# apollo3p register map
Vendor: Ambiq Micro; Series: Apollo; File version: 1.0
CPU: CM4 r1p0, little endian, MPU, FPU, I-cache, D-cache, VTOR, ITCM, DTCM, 3 interrupt priority bits, 0 interrupts
Registers are 32-bit, read-write, reset 0x0 unless marked. A register's access mark holds for its fields unless they carry their own. Offsets are from the block's base; [hi:lo] are bit positions; {n}, {i} and the like mark numbered series; 'fields as' and 'values as' point back to an identical list.

## MCUCTRL — MCU Miscellaneous Control Logic
Base 0x40020000
0x00 CHIPPN reset 0x6000000 — Chip Information Register
  [31:0] PARTNUM — BCD part number.
    0x7000000=APOLLO3P (Apollo3 Blue Plus part number is 0x07xxxxxx.); 0x6000000=APOLLO3 (Apollo3 Blue part number is 0x06xxxxxx.); 0x3000000=APOLLO2 (Apollo2 part number is 0x03xxxxxx.); 0x1000000=APOLLO (Apollo part number is 0x01xxxxxx.); 0xFF000000=PN_M (Mask for the part number field.); 24=PN_S (Bit position for the part number field.); 0xF00000=FLASHSIZE_M (Mask for the FLASH_SIZE field. Values: 0: 16KB 1: 32KB 2: 64KB 3: 128KB 4: 256KB 5: 512KB 6: 1MB 7: 2MB 8: 1.5MB); 20=FLASHSIZE_S (Bit position for the FLASH_SIZE field.); 0xF0000=SRAMSIZE_M (Mask for the SRAM_SIZE field. Values: 0: 16KB 1: 32KB 2: 64KB 3: 128KB 4: 256KB 5: 512KB 6: 1MB 7: 384KB 8: 768KB); 16=SRAMSIZE_S (Bit position for the SRAM_SIZE field.); 0xFF00=REV_M (Mask for the revision field. Bits [15:12] are major rev, [11:8] are minor rev. Values: 0: Major Rev A, Minor Rev 0 1: Major Rev B, Minor Rev 1); 8=REV_S (Bit position for the revision field.); 192=PKG_M (Mask for the package field. Values: 0: SIP 1: QFN 2: BGA 3: CSP); 6=PKG_S (Bit position for the package field.); 56=PINS_M (Mask for the pins field. Values: 0: 25 pins 1: 49 pins 2: 64 pins 3: 81 pins); 3=PINS_S (Bit position for the pins field.); 1=TEMP_S (Bit position for the temperature field.)
0x04 CHIPID0 — Unique Chip ID 0
  [31:0] CHIPID0 — Unique chip ID 0.
    0=APOLLO3 (Apollo3 Blue Plus CHIPID0.)
0x08 CHIPID1 — Unique Chip ID 1
  [31:0] CHIPID1 — Unique chip ID 1.
    0=APOLLO3 (Apollo3 Blue Plus CHIPID1.)
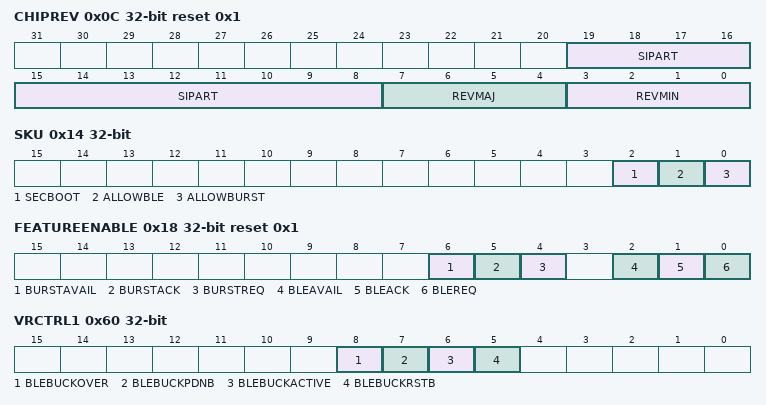
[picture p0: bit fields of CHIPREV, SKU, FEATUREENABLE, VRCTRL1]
0x0C CHIPREV reset 0x1 — Chip Revision
  [19:8] SIPART — Silicon Part ID
  [7:4] REVMAJ — Major Revision ID.
    3=C (Apollo3 Blue Plus); 2=B (Apollo3 Blue revision B); 1=A (Apollo3 Blue revision A)
  [3:0] REVMIN — Minor Revision ID.
    2=REV1 (Apollo3 Blue minor rev 1.); 1=REV0 (Apollo3 Blue minor rev 0. Minor revision value, succeeding minor revisions will increment from this value.)
0x10 VENDORID — Unique Vendor ID
  [31:0] VENDORID
    0x414D4251=AMBIQ (Ambiq Vendor ID 'AMBQ')
0x14 SKU — Unique Chip SKU
  [2] SECBOOT — Secure boot feature allowed
  [1] ALLOWBLE — Allow BLE feature
  [0] ALLOWBURST — Allow Burst feature
0x18 FEATUREENABLE reset 0x1 — Feature Enable on Burst and BLE
  [6] BURSTAVAIL — Availability of Burst functionality
    1=AVAIL (Burst functionality available); 0=NOTAVAIL (Burst functionality not available)
  [5] BURSTACK — ACK for BURSTREQ
  [4] BURSTREQ — Controls the Burst functionality
    1=EN (Enable the Burst functionality); 0=DIS (Disable the Burst functionality)
  [2] BLEAVAIL — AVAILABILITY of the BLE functionality
    1=AVAIL (BLE functionality available); 0=NOTAVAIL (BLE functionality not available)
  [1] BLEACK — ACK for BLEREQ
  [0] BLEREQ — Controls the BLE functionality
    1=EN (Enable the BLE functionality); 0=DIS (Disable the BLE functionality)
0x20 DEBUGGER — Debugger Control
  [0] LOCKOUT — Lockout of debugger (SWD).
0x38 DMASRAMWRITEPROTECT2 — These bits write-protect system SRAM from DMA operations in 8KB chunks.
  [31:0] DMA_WPROT2 — Write protect SRAM from DMA. Each bit provides write protection for an 8KB region of memory. When set to 1, the region will be protected from DMA writes, when set to 0, DMA may write the region.
0x60 VRCTRL1 — PRIMARY Voltage Regulator Control
  [8] BLEBUCKOVER — Override control for BLE BUCK signals
  [7] BLEBUCKPDNB — BLE BUCK PDNB control. Override for PWRCTRL going to analog when BLEBUCKOVER = 1
  [6] BLEBUCKACTIVE — BLE BUCK ACTIVE control. Override for PWRCTRL going to analog when BLEBUCKOVER = 1
  [5] BLEBUCKRSTB — BLE BUCK RSTB control. Override for PWRCTRL going to analog when BLEBUCKOVER = 1
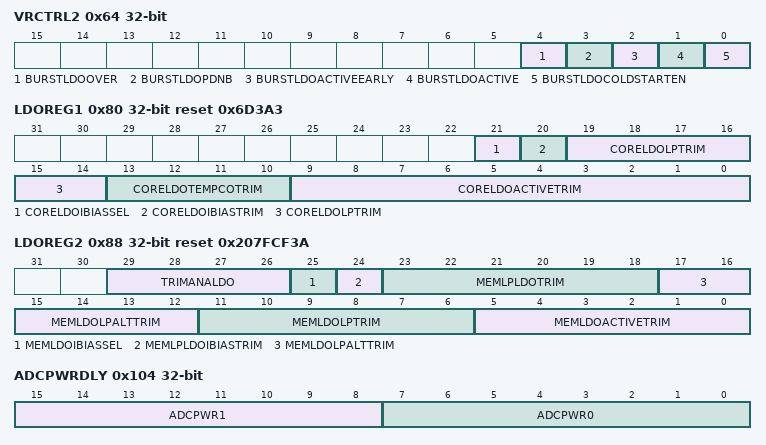
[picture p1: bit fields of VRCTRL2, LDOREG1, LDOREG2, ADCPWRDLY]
0x64 VRCTRL2 — SECONDARY Voltage Regulator Control
  [4] BURSTLDOOVER — Override control for BURST LDO signals
  [3] BURSTLDOPDNB — BURST LDO PDNB control. Override for PWRCTRL going to analog when BURSTLDOOVER = 1
  [2] BURSTLDOACTIVEEARLY — BURST LDO EARLY ACTIVE control. Override for PWRCTRL going to analog when BURSTLDOOVER = 1
  [1] BURSTLDOACTIVE — BURST LDO ACTIVE control. Override for PWRCTRL going to analog when BURSTLDOOVER = 1
  [0] BURSTLDOCOLDSTARTEN — BURST LDO COLDSTART EN control. Override for PWRCTRL going to analog when BURSTLDOOVER = 1
0x80 LDOREG1 reset 0x6D3A3 — CORELDO trims Reg
  [21] CORELDOIBIASSEL — Core LDO Ibias select. Note: the SWE mux select in PWRSEQ2SWE must be set for this to take effect.
  [20] CORELDOIBIASTRIM
  [19:14] CORELDOLPTRIM — CORE LDO Low Power Trim
  [13:10] CORELDOTEMPCOTRIM
  [9:0] CORELDOACTIVETRIM
0x88 LDOREG2 reset 0x207FCF3A — MEMLDO and MEMLPLDO Trims
  [29:26] TRIMANALDO — Analog LDO Trim
  [25] MEMLDOIBIASSEL — Mem LDO Ibias select. Note: the SWE mux select in PWRSEQ2SWE must be set for this to take effect.
  [24] MEMLPLDOIBIASTRIM
  [23:18] MEMLPLDOTRIM
  [17:12] MEMLDOLPALTTRIM — Mem LDO trim LP alternate set
  [11:6] MEMLDOLPTRIM
  [5:0] MEMLDOACTIVETRIM
0x104 ADCPWRDLY — ADC Power Up Delay Control
  [15:8] ADCPWR1 — ADC Reference Keeper enable delay in 16 ADC CLK increments for ADC_CLKSEL = 0x1, 8 ADC CLOCK increments for ADC_CLKSEL = 0x2.
  [7:0] ADCPWR0 — ADC Reference Buffer Power Enable delay in 64 ADC CLK increments for ADC_CLKSEL = 0x1, 32 ADC CLOCK increments for ADC_CLKSEL = 0x2.
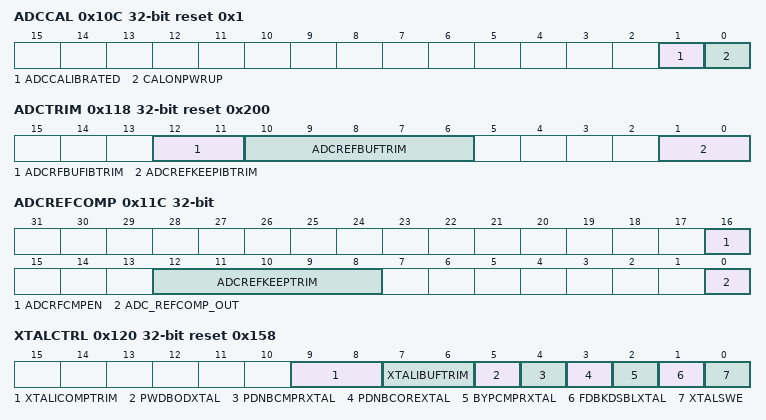
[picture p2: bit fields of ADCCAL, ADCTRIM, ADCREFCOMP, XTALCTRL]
0x10C ADCCAL reset 0x1 — ADC Calibration Control
  [1] ADCCALIBRATED — Status for ADC Calibration
    0=FALSE (ADC is not calibrated); 1=TRUE (ADC is calibrated)
  [0] CALONPWRUP — Run ADC Calibration on initial power up sequence
    0=DIS (Disable automatic calibration on initial power up); 1=EN (Enable automatic calibration on initial power up)
0x110 ADCBATTLOAD — ADC Battery Load Enable
  [0] BATTLOAD — Enable the ADC battery load resistor
    0=DIS (Battery load is disconnected); 1=EN (Battery load is enabled)
0x118 ADCTRIM reset 0x200 — ADC Trims
  [12:11] ADCRFBUFIBTRIM — ADC reference buffer input bias trim
  [10:6] ADCREFBUFTRIM — ADC Reference buffer trim
  [1:0] ADCREFKEEPIBTRIM — ADC Reference Ibias trim
0x11C ADCREFCOMP — ADC Reference Keeper and Comparator Control
  [16] ADCRFCMPEN — ADC Reference comparator power down
  [12:8] ADCREFKEEPTRIM — ADC Reference Keeper Trim
  [0] ADC_REFCOMP_OUT — Output of the ADC reference comparator
0x120 XTALCTRL reset 0x158 — XTAL Oscillator Control
  [9:8] XTALICOMPTRIM
  [7:6] XTALIBUFTRIM — XTAL IBUFF trim
  [5] PWDBODXTAL — XTAL Power down on brown out.
    0=PWRUPBOD (Power up XTAL on BOD.); 1=PWRDNBOD (Power down XTAL on BOD.)
  [4] PDNBCMPRXTAL — XTAL Oscillator Power Down Comparator.
    1=PWRUPCOMP (Power up XTAL oscillator comparator.); 0=PWRDNCOMP (Power down XTAL oscillator comparator.)
  [3] PDNBCOREXTAL — XTAL Oscillator Power Down Core.
    1=PWRUPCORE (Power up XTAL oscillator core.); 0=PWRDNCORE (Power down XTAL oscillator core.)
  [2] BYPCMPRXTAL — XTAL Oscillator Bypass Comparator.
    0=USECOMP (Use the XTAL oscillator comparator.); 1=BYPCOMP (Bypass the XTAL oscillator comparator.)
  [1] FDBKDSBLXTAL — XTAL Oscillator Disable Feedback.
    0=EN (Enable XTAL oscillator comparator.); 1=DIS (Disable XTAL oscillator comparator.)
  [0] XTALSWE — XTAL Software Override Enable.
    0=OVERRIDE_DIS (XTAL Software Override Disable.); 1=OVERRIDE_EN (XTAL Software Override Enable.)
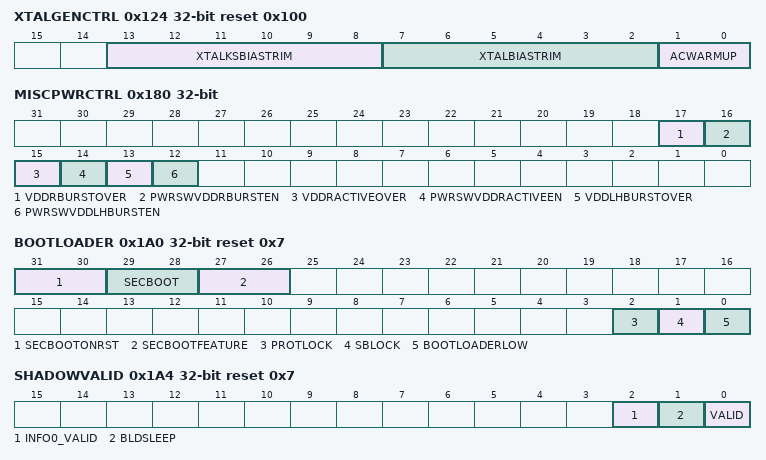
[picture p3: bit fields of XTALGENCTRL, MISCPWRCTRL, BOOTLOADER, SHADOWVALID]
0x124 XTALGENCTRL reset 0x100 — XTAL Oscillator General Control
  [13:8] XTALKSBIASTRIM — XTAL IBIAS Kick start trim. This trim value is used during the startup process to enable a faster lock.
  [7:2] XTALBIASTRIM
  [1:0] ACWARMUP — Auto-calibration delay control
    0=SEC1 (Warm-up period of 1-2 seconds); 1=SEC2 (Warm-up period of 2-4 seconds); 2=SEC4 (Warm-up period of 4-8 seconds); 3=SEC8 (Warm-up period of 8-16 seconds)
0x180 MISCPWRCTRL — MISC power control override
  [17] VDDRBURSTOVER — pwrsw_vddr_burst_en override control
    1=EN (Writing a '1' will enable this register to override pwrsw_vddr_burst_en control signals from pwrctrl to mcu_ctrl)
  [16] PWRSWVDDRBURSTEN — override for pwrsw_vddr_burst_en
  [15] VDDRACTIVEOVER — pwrsw_vddr_active_en override control
    1=EN (Writing a '1' will enable this register to override pwrsw_vddr_active_en control signals from pwrctrl to mcu_ctrl)
  [14] PWRSWVDDRACTIVEEN — override for pwrsw_vddr_active_en
  [13] VDDLHBURSTOVER — pwrsw_vddlh_burst_en override control
    1=EN (Writing a '1' will enable this register to override pwrsw_vddlh_burst_en control signals from pwrctrl to mcu_ctrl)
  [12] PWRSWVDDLHBURSTEN — override for pwrsw_vddlh_burst_en
0x198 MISCCTRL — Miscellaneous control register.
  [5] BLE_RESETN — BLE reset signal.
0x1A0 BOOTLOADER reset 0x7 — Bootloader and secure boot functions
  [31:30] SECBOOTONRST — Indicates whether the secure boot on warm reset is enabled
    0=DISABLED (Secure boot disabled); 1=ENABLED (Secure boot enabled); 2=ERROR (Error in secure boot configuration)
  [29:28] SECBOOT — Indicates whether the secure boot on cold reset is enabled
    values as SECBOOTONRST
  [27:26] SECBOOTFEATURE — Indicates whether the secure boot feature is enabled.
    values as SECBOOTONRST
  [2] PROTLOCK — Flash protection lock. Always resets to 1, write 1 to clear. Enables writes to flash protection register set.
    1=LOCK (Enable the secure boot lock)
  [1] SBLOCK — Secure boot lock. Always resets to 1, write 1 to clear. Enables system visibility to bootloader until set.
    1=LOCK (Enable the secure boot lock)
  [0] BOOTLOADERLOW — Determines whether the bootloader code is visible at address 0x00000000 or not. Resets to 1, write 1 to clear.
    1=ADDR0 (Bootloader code at 0x00000000.)
0x1A4 SHADOWVALID reset 0x7 — Register to indicate whether the shadow registers have been successfully loaded from the Flash Information Space.
  [2] INFO0_VALID — Indicates whether INFO0 contains valid data
    1=VALID (Flash INFO0 (customer) space contains valid data.)
  [1] BLDSLEEP — Indicates whether the bootloader should sleep or deep sleep if no image loaded.
    1=DEEPSLEEP (Bootloader will go to deep sleep if no flash image loaded)
  [0] VALID — Indicates whether the shadow registers contain valid data from the Flash Information Space.
    1=VALID (Flash information space contains valid data.)
0x1B0 SCRATCH0 — Scratch register that is not reset by any reset
  [31:0] SCRATCH0 — Scratch register 0.
0x1B4 SCRATCH1 — Scratch register that is not reset by any reset
  [31:0] SCRATCH1 — Scratch register 1.
0x1C0 ICODEFAULTADDR — ICODE bus address which was present when a bus fault occurred.
  [31:0] ICODEFAULTADDR — The ICODE bus address observed when a Bus Fault occurred. Once an address is captured in this field, it is held until the corresponding Fault Observed bit is cleared in the FAULTSTATUS register.
0x1C4 DCODEFAULTADDR — DCODE bus address which was present when a bus fault occurred.
  [31:0] DCODEFAULTADDR — The DCODE bus address observed when a Bus Fault occurred. Once an address is captured in this field, it is held until the corresponding Fault Observed bit is cleared in the FAULTSTATUS register.
0x1C8 SYSFAULTADDR — System bus address which was present when a bus fault occurred.
  [31:0] SYSFAULTADDR — SYS bus address observed when a Bus Fault occurred. Once an address is captured in this field, it is held until the corresponding Fault Observed bit is cleared in the FAULTSTATUS register.
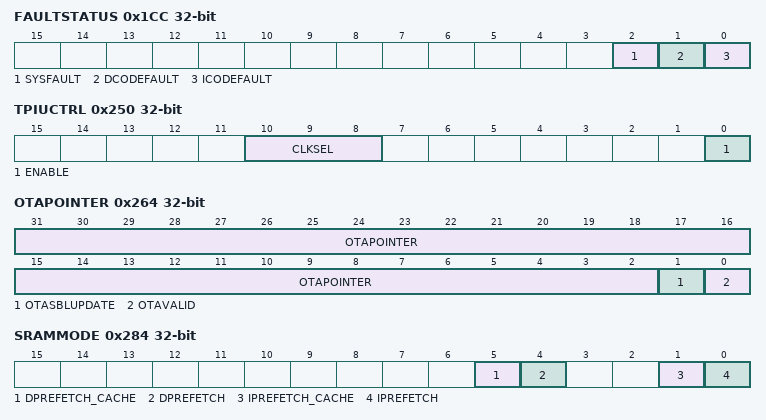
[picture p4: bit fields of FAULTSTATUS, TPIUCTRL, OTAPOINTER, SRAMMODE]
0x1CC FAULTSTATUS — Reflects the status of the bus decoders' fault detection. Any write to this register will clear all of the status bits within the register.
  [2] SYSFAULT — SYS Bus Decoder Fault Detected bit. When set, a fault has been detected, and the SYSFAULTADDR register will contain the bus address which generated the fault.
    0=NOFAULT (No bus fault has been detected.); 1=FAULT (Bus fault detected.)
  [1] DCODEFAULT — DCODE Bus Decoder Fault Detected bit. When set, a fault has been detected, and the DCODEFAULTADDR register will contain the bus address which generated the fault.
    0=NOFAULT (No DCODE fault has been detected.); 1=FAULT (DCODE fault detected.)
  [0] ICODEFAULT — The ICODE Bus Decoder Fault Detected bit. When set, a fault has been detected, and the ICODEFAULTADDR register will contain the bus address which generated the fault.
    0=NOFAULT (No ICODE fault has been detected.); 1=FAULT (ICODE fault detected.)
0x1D0 FAULTCAPTUREEN — Enable the fault capture registers
  [0] FAULTCAPTUREEN — Fault Capture Enable field. When set, the Fault Capture monitors are enabled and addresses which generate a hard fault are captured into the FAULTADDR registers.
    0=DIS (Disable fault capture.); 1=EN (Enable fault capture.)
0x200 DBGR1 reset 0x12345678 — Read-only debug register 1
  [31:0] ONETO8 — Read-only register for communication validation
0x204 DBGR2 reset 0xC001C0DE — Read-only debug register 2
  [31:0] COOLCODE — Read-only register for communication validation
0x220 PMUENABLE reset 0x1 — Control bit to enable/disable the PMU
  [0] ENABLE — PMU Enable Control bit. When set, the MCU's PMU will place the MCU into the lowest power consuming Deep Sleep mode upon execution of a WFI instruction (dependent on the setting of the SLEEPDEEP bit in the ARM SCR register). When cleared, regardless of the requested sleep mode, the PMU will not enter the lowest power Deep Sleep mode, instead entering the Sleep mode.
    0=DIS (Disable MCU power management.); 1=EN (Enable MCU power management.)
0x250 TPIUCTRL — TPIU Control Register. Determines the clock enable and frequency for the M4's TPIU interface.
  [10:8] CLKSEL — This field selects the frequency of the ARM M4 TPIU port.
    0=LOWPWR (Low power state.); 1=HFRCDIV2 (Selects HFRC divided by 2 as the source TPIU clock); 2=HFRCDIV8 (Selects HFRC divided by 8 as the source TPIU clock); 3=HFRCDIV16 (Selects HFRC divided by 16 as the source TPIU clock); 4=HFRCDIV32 (Selects HFRC divided by 32 as the source TPIU clock)
  [0] ENABLE — TPIU Enable field. When set, the ARM M4 TPIU is enabled and data can be streamed out of the MCU's SWO port using the ARM ITM and TPIU modules.
    0=DIS (Disable the TPIU.); 1=EN (Enable the TPIU.)
0x264 OTAPOINTER — OTA (Over the Air) Update Pointer/Status. Reset only by POA
  [31:2] OTAPOINTER — Flash page pointer with updated OTA image
  [1] OTASBLUPDATE — Indicates that the sbl_init has been updated
  [0] OTAVALID — Indicates that an OTA update is valid
0x284 SRAMMODE — SRAM Controller mode bits
  [5] DPREFETCH_CACHE — Secondary pre-fetch feature that will cache pre-fetched data across bus wait states (requires DPREFETCH to be set).
  [4] DPREFETCH — When set, data bus accesses to the SRAM banks will be pre-fetched (normally 2 cycle read access). Use of this mode bit is only recommended if the work flow has a large number of sequential accesses.
  [1] IPREFETCH_CACHE — Secondary pre-fetch feature that will cache pre-fetched data across bus wait states (requires IPREFETCH to be set).
  [0] IPREFETCH — When set, instruction accesses to the SRAM banks will be pre-fetched (normally 2 cycle read access). Generally, this mode bit should be set for improved performance when executing instructions from SRAM.
0x348 KEXTCLKSEL — Locks the state of the EXTCLKSEL register from writes. This is done to prevent errant writes to the register, as this could cause the chip to halt. Write a value of 0x53 to unlock write access to the EXTCLKSEL register. Once unlocked, the register will read back a 1 to indicate this is unlocked. Writing the register with any other value other than 0x53 will enable the lock.
  [31:0] KEXTCLKSEL — Key register value.
    83=Key (Key value to unlock the register.)
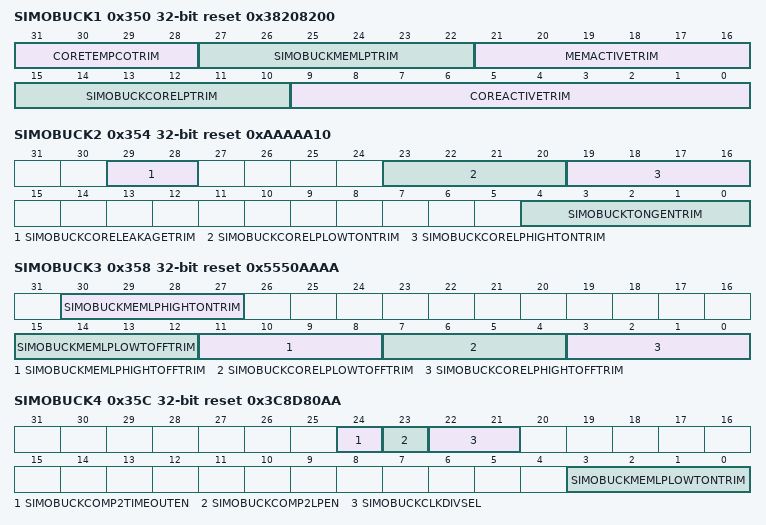
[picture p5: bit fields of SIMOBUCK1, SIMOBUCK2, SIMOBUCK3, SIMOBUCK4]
0x350 SIMOBUCK1 reset 0x38208200 — SIMO Buck Control Reg 1
  [31:28] CORETEMPCOTRIM — simobuck_core_tempco_trim
  [27:22] SIMOBUCKMEMLPTRIM
  [21:16] MEMACTIVETRIM — simobuck_mem_active_trim (VDDC)
  [15:10] SIMOBUCKCORELPTRIM
  [9:0] COREACTIVETRIM — simobuck_core_active_trim (VDDF)
0x354 SIMOBUCK2 reset 0xAAAAA10 — SIMO Buck Control Reg 2
  [29:28] SIMOBUCKCORELEAKAGETRIM, [23:20] SIMOBUCKCORELPLOWTONTRIM, [19:16] SIMOBUCKCORELPHIGHTONTRIM, [4:0] SIMOBUCKTONGENTRIM
0x358 SIMOBUCK3 reset 0x5550AAAA — SIMO Buck Control Reg 3
  [30:27] SIMOBUCKMEMLPHIGHTONTRIM, [15:12] SIMOBUCKMEMLPLOWTOFFTRIM, [11:8] SIMOBUCKMEMLPHIGHTOFFTRIM, [7:4] SIMOBUCKCORELPLOWTOFFTRIM, [3:0] SIMOBUCKCORELPHIGHTOFFTRIM
0x35C SIMOBUCK4 reset 0x3C8D80AA — SIMO Buck Control Reg 4
  [24] SIMOBUCKCOMP2TIMEOUTEN, [23] SIMOBUCKCOMP2LPEN, [22:21] SIMOBUCKCLKDIVSEL, [3:0] SIMOBUCKMEMLPLOWTONTRIM
0x364 BLEBUCK1 — BLEBUCK1 Control Reg
  [18:15] BLEBUCKPULLUPTRIM
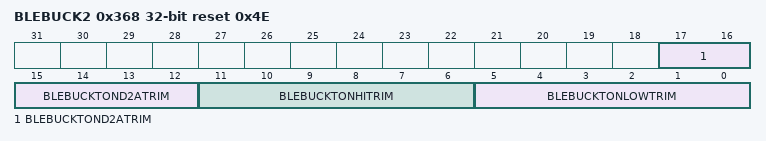
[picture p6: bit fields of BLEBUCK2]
0x368 BLEBUCK2 reset 0x4E — BLEBUCK2 Control Reg
  [17:12] BLEBUCKTOND2ATRIM — blebuck_ton_trim
  [11:6] BLEBUCKTONHITRIM
  [5:0] BLEBUCKTONLOWTRIM
{0x3A0+4i} FLASHWPROT{i} (i=0..3) — These bits write-protect flash in 16KB chunks.
  [31:0] FW{i}BITS — Write protect flash {0x0+0x80000*i} - {0x7FFFF+0x80000*i}. Each bit provides write protection for 16KB chunks of flash data space. Bits are cleared by writing a 1 to the bit. When read, 0 indicates the region is protected. Bits are sticky (can be set when PROTLOCK is 1, but only cleared by reset)
{0x3B0+4i} FLASHRPROT{i} (i=0..3) — These bits read-protect flash in 16KB chunks.
  [31:0] FR{i}BITS — Copy (read) protect flash {0x0+0x80000*i} - {0x7FFFF+0x80000*i}. Each bit provides read protection for 16KB chunks of flash. Bits are cleared by writing a 1 to the bit. When read, 0 indicates the region is protected. Bits are sticky (can be set when PROTLOCK is 1, but only cleared by reset)
0x3C0 DMASRAMWRITEPROTECT0 — These bits write-protect system SRAM from DMA operations in 8KB chunks.
  [31:0] DMA_WPROT0 — Write protect SRAM from DMA. Each bit provides write protection for an 8KB region of memory. When set to 1, the region will be protected from DMA writes, when set to 0, DMA may write the region.
0x3C4 DMASRAMWRITEPROTECT1 — These bits write-protect system SRAM from DMA operations in 8KB chunks.
  [31:0] DMA_WPROT1 — Write protect SRAM from DMA. Each bit provides write protection for an 8KB region of memory. When set to 1, the region will be protected from DMA writes, when set to 0, DMA may write the region.
{0x3D0+4i} DMASRAMREADPROTECT{i} (i=0..2) — These bits read-protect system SRAM from DMA operations in 8KB chunks.
  [31:0] DMA_RPROT{i} — Read protect SRAM from DMA. Each bit provides write protection for an 8KB region of memory. When set to 1, the region will be protected from DMA reads, when set to 0, DMA may read the region.
